# XMC3050 register map
Vendor: Infineon; File version: 1.5.3 (Reference Manual v1.5)
CPU: CM4 r2p0, little endian, MPU, FPU, 6 interrupt priority bits
Registers are 32-bit, read-write, reset 0x0 unless marked. A register's access mark holds for its fields unless they carry their own. Offsets are from the block's base; [hi:lo] are bit positions.

## SCU_PARITY — System Control Unit
Base 0x5000413C
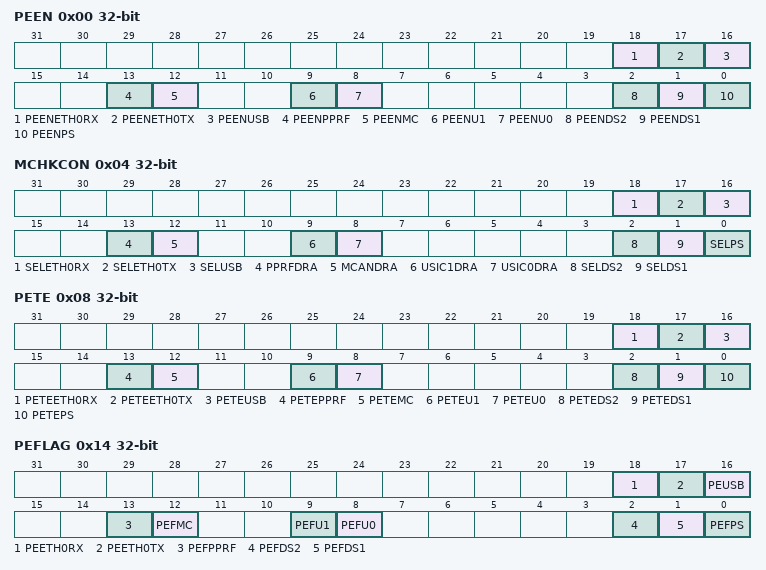
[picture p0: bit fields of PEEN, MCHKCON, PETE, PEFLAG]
0x00 PEEN — Parity Error Enable Register
  [all] fields
    0=Disabled; 1=Enabled
  [18] PEENETH0RX — Parity Error Enable for ETH RX Memory
  [17] PEENETH0TX — Parity Error Enable for ETH TX Memory
  [16] PEENUSB — Parity Error Enable for USB Memory
  [13] PEENPPRF — Parity Error Enable for PMU Prefetch Memory
  [12] PEENMC — Parity Error Enable for MultiCAN Memory
  [9] PEENU1 — Parity Error Enable for USIC1 Memory
  [8] PEENU0 — Parity Error Enable for USIC0 Memory
  [2] PEENDS2 — Parity Error Enable for DSRAM2
  [1] PEENDS1 — Parity Error Enable for DSRAM1
  [0] PEENPS — Parity Error Enable for PSRAM
0x04 MCHKCON — Memory Checking Control Register
  [all] fields
    0=Not selected; 1=Selected
  [18] SELETH0RX — Select Memory Check for ETH0 RX SRAM
  [17] SELETH0TX — Select Memory Check for ETH0 TX SRAM
  [16] SELUSB — Select Memory Check for USB SRAM
  [13] PPRFDRA — Select Memory Check for PMU
  [12] MCANDRA — Select Memory Check for MultiCAN
  [9] USIC1DRA — Select Memory Check for USIC1
  [8] USIC0DRA — Select Memory Check for USIC0
  [2] SELDS2 — Select Memory Check for DSRAM2
  [1] SELDS1 — Select Memory Check for DSRAM1
  [0] SELPS — Select Memory Check for PSRAM
0x08 PETE — Parity Error Trap Enable Register
  [all] fields
    0=Disabled; 1=Enabled
  [18] PETEETH0RX — Parity Error Trap Enable for ETH0 RX Memory
  [17] PETEETH0TX — Parity Error Trap Enable for ETH 0TX Memory
  [16] PETEUSB — Parity Error Trap Enable for USB Memory
  [13] PETEPPRF — Parity Error Trap Enable for PMU Prefetch Memory
  [12] PETEMC — Parity Error Trap Enable for MultiCAN Memory
  [9] PETEU1 — Parity Error Trap Enable for USIC1 Memory
  [8] PETEU0 — Parity Error Trap Enable for USIC0 Memory
  [2] PETEDS2 — Parity Error Trap Enable for DSRAM2
  [1] PETEDS1 — Parity Error Trap Enable for DSRAM1
  [0] PETEPS — Parity Error Trap Enable for PSRAM
0x0C PERSTEN — Parity Error Reset Enable Register
  [0] RSEN — System Reset Enable upon Parity Error Trap
    0=Reset request disabled; 1=Reset request enabled
0x14 PEFLAG — Parity Error Flag Register
  [all] fields
    0=No parity error detected; 1=Parity error detected
  [18] PEETH0RX — Parity Error Flag for ETH RX Memory
  [17] PEETH0TX — Parity Error Flag for ETH TX Memory
  [16] PEUSB — Parity Error Flag for USB Memory
  [13] PEFPPRF — Parity Error Flag for PMU Prefetch Memory
  [12] PEFMC — Parity Error Flag for MultiCAN Memory
  [9] PEFU1 — Parity Error Flag for USIC1 Memory
  [8] PEFU0 — Parity Error Flag for USIC0 Memory
  [2] PEFDS2 — Parity Error Flag for DSRAM2
  [1] PEFDS1 — Parity Error Flag for DSRAM1
  [0] PEFPS — Parity Error Flag for PSRAM
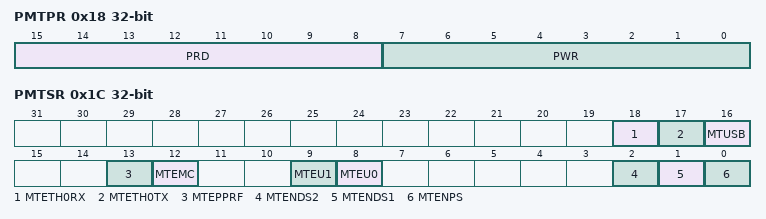
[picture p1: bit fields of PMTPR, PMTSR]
0x18 PMTPR access per field — Parity Memory Test Pattern Register
  [15:8] PRD ro — Parity Read Values for Memory Test
  [7:0] PWR rw — Parity Write Values for Memory Test
0x1C PMTSR — Parity Memory Test Select Register
  [all] fields
    0=Standard operation; 1=Parity bits under test
  [18] MTETH0RX — Test Enable Control for ETH RX Memory
  [17] MTETH0TX — Test Enable Control for ETH TX Memory
  [16] MTUSB — Test Enable Control for USB Memory
  [13] MTEPPRF — Test Enable Control for PMU Prefetch Memory
  [12] MTEMC — Test Enable Control for MultiCAN Memory
  [9] MTEU1 — Test Enable Control for USIC1 Memory
  [8] MTEU0 — Test Enable Control for USIC0 Memory
  [2] MTENDS2 — Test Enable Control for DSRAM2
  [1] MTENDS1 — Test Enable Control for DSRAM1
  [0] MTENPS — Test Enable Control for PSRAM

## SCU_TRAP — System Control Unit
Base 0x50004160
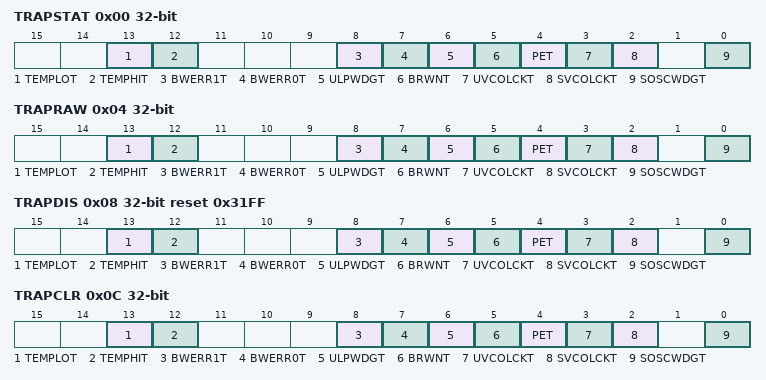
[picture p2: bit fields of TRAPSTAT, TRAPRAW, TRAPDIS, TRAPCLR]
0x00 TRAPSTAT ro — Trap Status Register
  [all] fields
    0=No pending trap request; 1=Pending trap request
  [13] TEMPLOT — Die Temperature Too Low Trap Status
  [12] TEMPHIT — Die Temperature Too High Trap Status
  [8] BWERR1T — Peripheral Bridge 1 Trap Status
  [7] BWERR0T — Peripheral Bridge 0 Trap Status
  [6] ULPWDGT — OSC_ULP WDG Trap Status
  [5] BRWNT — Brown Out Trap Status
  [4] PET — Parity Error Trap Status
  [3] UVCOLCKT — USB VCO Lock Trap Status
  [2] SVCOLCKT — System VCO Lock Trap Status
  [0] SOSCWDGT — System OSC WDT Trap Status
0x04 TRAPRAW ro — Trap Raw Status Register
  [all] fields
    0=No pending trap request; 1=Pending trap request
  [13] TEMPLOT — Die Temperature Too Low Trap Raw Status
  [12] TEMPHIT — Die Temperature Too High Trap Raw Status
  [8] BWERR1T — Peripheral Bridge 1 Trap Raw Status
  [7] BWERR0T — Peripheral Bridge 0 Trap Raw Status
  [6] ULPWDGT — OSC_ULP WDG Trap RAW Status
  [5] BRWNT — Brown Out Trap Raw Status
  [4] PET — Parity Error Trap Raw Status
  [3] UVCOLCKT — USB VCO Lock Trap Raw Status
  [2] SVCOLCKT — System VCO Lock Trap Raw Status
  [0] SOSCWDGT — System OSC WDT Trap Raw Status
0x08 TRAPDIS reset 0x31FF — Trap Disable Register
  [all] fields
    0=Trap request enabled; 1=Trap request disabled
  [13] TEMPLOT — Die Temperature Too Low Trap Disable
  [12] TEMPHIT — Die Temperature Too High Trap Disable
  [8] BWERR1T — Peripheral Bridge 1 Trap Disable
  [7] BWERR0T — Peripheral Bridge 0 Trap Disable
  [6] ULPWDGT — Wake-up Trap Disable
  [5] BRWNT — Brown Out Trap Disable
  [4] PET — Parity Error Trap Disable
  [3] UVCOLCKT — USB VCO Lock Trap Disable
  [2] SVCOLCKT — System VCO Lock Trap Disable
  [0] SOSCWDGT — System OSC WDT Trap Disable
0x0C TRAPCLR wo — Trap Clear Register
  [all] fields
    0=No effect; 1=Clear trap request
  [13] TEMPLOT — Die Temperature Too Low Trap Clear
  [12] TEMPHIT — Die Temperature Too High Trap Clear
  [8] BWERR1T — Peripheral Bridge 1 Trap Clear
  [7] BWERR0T — Peripheral Bridge 0 Trap Clear
  [6] ULPWDGT — OSC_ULP WDG Trap Clear
  [5] BRWNT — Brown Out Trap Clear
  [4] PET — Parity Error Trap Clear
  [3] UVCOLCKT — USB VCO Lock Trap Clear
  [2] SVCOLCKT — System VCO Lock Trap Clear
  [0] SOSCWDGT — System OSC WDT Trap Clear
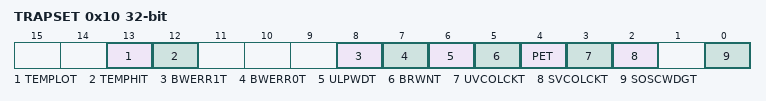
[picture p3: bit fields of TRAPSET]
0x10 TRAPSET wo
  [all] fields
    0=No effect; 1=Set trap request
  [13] TEMPLOT — Die Temperature Too Low Trap Set
  [12] TEMPHIT — Die Temperature Too High Trap Set
  [8] BWERR1T — Peripheral Bridge 1 Trap Set
  [7] BWERR0T — Peripheral Bridge 0 Trap Set
  [6] ULPWDT — OSC_ULP WDG Trap Set
  [5] BRWNT — Brown Out Trap Set
  [4] PET — Parity Error Trap Set
  [3] UVCOLCKT — USB VCO Lock Trap Set
  [2] SVCOLCKT — System VCO Lock Trap Set
  [0] SOSCWDGT — System OSC WDT Trap Set
